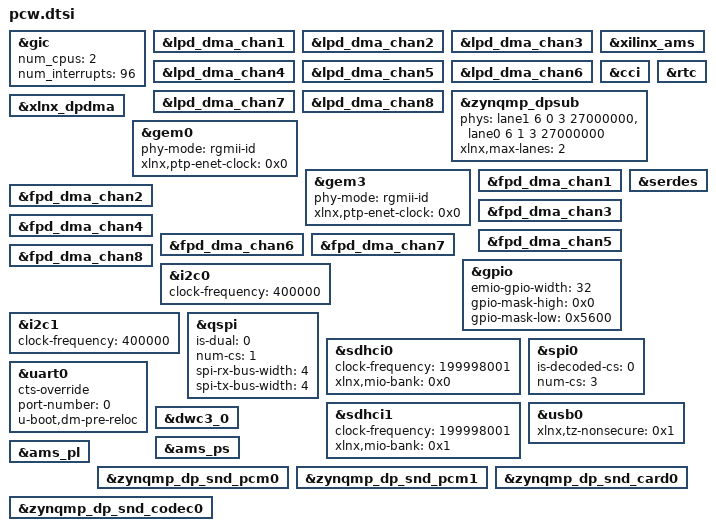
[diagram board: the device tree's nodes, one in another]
/*
 * CAUTION: This file is automatically generated by Xilinx.
 * Version:  
 * Today is: Sat Sep  2 12:16:36 2023
 */


&gic {
	num_cpus = <2>;
	num_interrupts = <96>;
};
&lpd_dma_chan1 {
	status = "okay";
};
&lpd_dma_chan2 {
	status = "okay";
};
&lpd_dma_chan3 {
	status = "okay";
};
&lpd_dma_chan4 {
	status = "okay";
};
&lpd_dma_chan5 {
	status = "okay";
};
&lpd_dma_chan6 {
	status = "okay";
};
&lpd_dma_chan7 {
	status = "okay";
};
&lpd_dma_chan8 {
	status = "okay";
};
&xilinx_ams {
	status = "okay";
};
&cci {
	status = "okay";
};
&zynqmp_dpsub {
	phy-names = "dp-phy0","dp-phy1";
	phys = <&lane1 6 0 3 27000000>, <&lane0 6 1 3 27000000>;
	status = "okay";
	xlnx,max-lanes = <2>;
};
&xlnx_dpdma {
	status = "okay";
};
&gem0 {
	phy-mode = "rgmii-id";
	status = "okay";
	xlnx,ptp-enet-clock = <0x0>;
};
&gem3 {
	phy-mode = "rgmii-id";
	status = "okay";
	xlnx,ptp-enet-clock = <0x0>;
};
&fpd_dma_chan1 {
	status = "okay";
};
&fpd_dma_chan2 {
	status = "okay";
};
&fpd_dma_chan3 {
	status = "okay";
};
&fpd_dma_chan4 {
	status = "okay";
};
&fpd_dma_chan5 {
	status = "okay";
};
&fpd_dma_chan6 {
	status = "okay";
};
&fpd_dma_chan7 {
	status = "okay";
};
&fpd_dma_chan8 {
	status = "okay";
};
&gpio {
	emio-gpio-width = <32>;
	gpio-mask-high = <0x0>;
	gpio-mask-low = <0x5600>;
	status = "okay";
};
&i2c0 {
	clock-frequency = <400000>;
	status = "okay";
};
&i2c1 {
	clock-frequency = <400000>;
	status = "okay";
};
&qspi {
	is-dual = <0>;
	num-cs = <1>;
	spi-rx-bus-width = <4>;
	spi-tx-bus-width = <4>;
	status = "okay";
};
&rtc {
	status = "okay";
};
&sdhci0 {
	clock-frequency = <199998001>;
	status = "okay";
	xlnx,mio-bank = <0x0>;
};
&sdhci1 {
	clock-frequency = <199998001>;
	status = "okay";
	xlnx,mio-bank = <0x1>;
};
&serdes {
	status = "okay";
};
&spi0 {
	is-decoded-cs = <0>;
	num-cs = <3>;
	status = "okay";
};
&uart0 {
	cts-override ;
	device_type = "serial";
	port-number = <0>;
	status = "okay";
	u-boot,dm-pre-reloc ;
};
&usb0 {
	status = "okay";
	xlnx,tz-nonsecure = <0x1>;
};
&dwc3_0 {
	status = "okay";
};
&ams_ps {
	status = "okay";
};
&ams_pl {
	status = "okay";
};
&zynqmp_dp_snd_pcm0 {
	status = "okay";
};
&zynqmp_dp_snd_pcm1 {
	status = "okay";
};
&zynqmp_dp_snd_card0 {
	status = "okay";
};
&zynqmp_dp_snd_codec0 {
	status = "okay";
};
